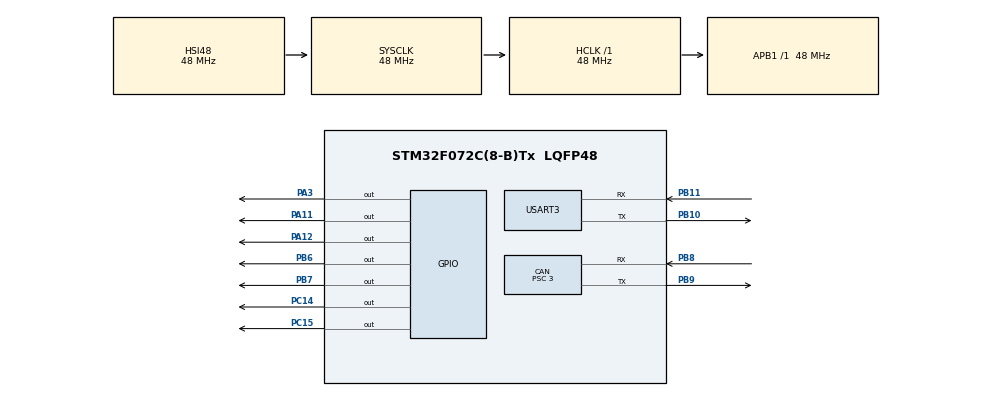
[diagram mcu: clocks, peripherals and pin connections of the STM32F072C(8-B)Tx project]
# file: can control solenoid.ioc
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CAN.BS1=CAN_BS1_12TQ
CAN.BS2=CAN_BS2_3TQ
CAN.CalculateBaudRate=1000000
CAN.CalculateTimeBit=1000
CAN.CalculateTimeQuantum=62.5
CAN.Prescaler=3
Mcu.Family=STM32F0
Mcu.Name=STM32F072C(8-B)Tx
Mcu.Package=LQFP48
NVIC.CEC_CAN_IRQn=true\:0\:0\:false\:false\:true\:true\:true\:true
PA11.Signal=GPIO_Output
PA12.Signal=GPIO_Output
PA13.Mode=Serial_Wire
PA13.Signal=SYS_SWDIO
PA14.Mode=Serial_Wire
PA14.Signal=SYS_SWCLK
PA3.Signal=GPIO_Output
PB10.Mode=Asynchronous
PB10.Signal=USART3_TX
PB11.Mode=Asynchronous
PB11.Signal=USART3_RX
PB6.Signal=GPIO_Output
PB7.Signal=GPIO_Output
PB8.Mode=CAN_Activate
PB8.Signal=CAN_RX
PB9.Mode=CAN_Activate
PB9.Signal=CAN_TX
PC14-OSC32_IN.Signal=GPIO_Output
PC15-OSC32_OUT.Signal=GPIO_Output
ProjectManager.HeapSize=0x200
ProjectManager.StackSize=0x400
ProjectManager.TargetToolchain=MDK-ARM V5.32
RCC.AHBFreq_Value=48000000
RCC.APB1Freq_Value=48000000
RCC.APB1TimFreq_Value=48000000
RCC.HCLKFreq_Value=48000000
RCC.SYSCLKFreq_VALUE=48000000
RCC.SYSCLKSource=RCC_SYSCLKSOURCE_HSI48
USART3.VirtualMode-Asynchronous=VM_ASYNC
board=custom

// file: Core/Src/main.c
/* USER CODE BEGIN Header */
/**
  ******************************************************************************
  * @file           : main.c
  * @brief          : Main program body
  ******************************************************************************
  * @attention
  *
  * Copyright (c) 2026 STMicroelectronics.
  * All rights reserved.
  *
  * This software is licensed under terms that can be found in the LICENSE file
  * in the root directory of this software component.
  * If no LICENSE file comes with this software, it is provided AS-IS.
  *
  ******************************************************************************
  */
/* USER CODE END Header */
#include "main.h"
#include "can.h"
#include "usart.h"
#include "gpio.h"

/* USER CODE BEGIN PD */
	uint8_t cmd;
/* USER CODE END PD */

/* USER CODE BEGIN PV */
uint32_t lastCanSend = 0;

/* USER CODE END PV */

void SystemClock_Config(void);

int main(void)
{

  /* MCU Configuration--------------------------------------------------------*/

  /* Reset of all peripherals, Initializes the Flash interface and the Systick. */
  HAL_Init();

  /* Configure the system clock */
  SystemClock_Config();

  /* Initialize all configured peripherals */
  MX_GPIO_Init();
  MX_CAN_Init();
  MX_USART3_UART_Init();
  /* USER CODE BEGIN 2 */
  //register_init();
  reciever_init(&hcan);

  /* USER CODE END 2 */

  /* Infinite loop */
  while (1)
  {

    /* USER CODE BEGIN 3 */
    // if (HAL_GetTick() - lastCanSend >= 1000U)
    // {
    //   lastCanSend = HAL_GetTick();
    //   if (CAN_Send20261025() != HAL_OK)
    //   {
    //     Error_Handler();
    //   }
    // }
  }
  /* USER CODE END 3 */
}

void SystemClock_Config(void)
{
  RCC_OscInitTypeDef RCC_OscInitStruct = {0};
  RCC_ClkInitTypeDef RCC_ClkInitStruct = {0};

  /** Initializes the RCC Oscillators according to the specified parameters
  * in the RCC_OscInitTypeDef structure.
  */
  RCC_OscInitStruct.OscillatorType = RCC_OSCILLATORTYPE_HSI48;
  RCC_OscInitStruct.HSI48State = RCC_HSI48_ON;
  RCC_OscInitStruct.PLL.PLLState = RCC_PLL_NONE;
  if (HAL_RCC_OscConfig(&RCC_OscInitStruct) != HAL_OK)
  {
    Error_Handler();
  }

  /** Initializes the CPU, AHB and APB buses clocks
  */
  RCC_ClkInitStruct.ClockType = RCC_CLOCKTYPE_HCLK|RCC_CLOCKTYPE_SYSCLK
                              |RCC_CLOCKTYPE_PCLK1;
  RCC_ClkInitStruct.SYSCLKSource = RCC_SYSCLKSOURCE_HSI48;
  RCC_ClkInitStruct.AHBCLKDivider = RCC_SYSCLK_DIV1;
  RCC_ClkInitStruct.APB1CLKDivider = RCC_HCLK_DIV1;

  if (HAL_RCC_ClockConfig(&RCC_ClkInitStruct, FLASH_LATENCY_1) != HAL_OK)
  {
    Error_Handler();
  }
}

void Error_Handler(void)
{
  __disable_irq();
  while (1)
  {
  }
}
